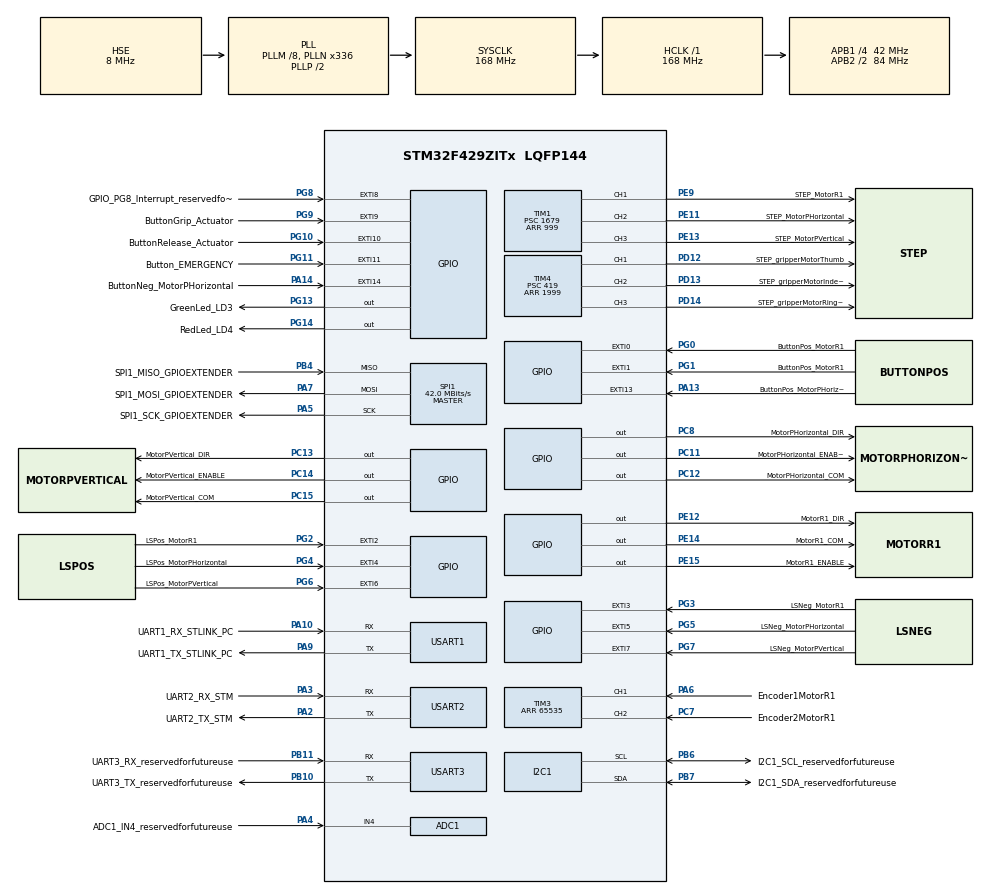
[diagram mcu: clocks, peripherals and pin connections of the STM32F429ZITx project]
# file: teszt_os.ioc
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ADC1.Channel-3\#ChannelRegularConversion=ADC_CHANNEL_4
ADC1.NbrOfConversionFlag=1
ADC1.Rank-3\#ChannelRegularConversion=1
ADC1.SamplingTime-3\#ChannelRegularConversion=ADC_SAMPLETIME_3CYCLES
ADC1.master=1
FREERTOS.BinarySemaphores01=semMotorR1,Dynamic,NULL;semMotorPHorizontal,Dynamic,NULL;semMotorPVertical,Dynamic,NULL
FREERTOS.INCLUDE_vTaskDelayUntil=1
FREERTOS.Queues01=commQueue,16,uint32_t,0,Dynamic,NULL,NULL
FREERTOS.Tasks01=defaultTask,0,256,StartDefaultTask,Default,NULL,Dynamic,NULL,NULL;controlTask,3,2048,StartRobotControlTask,Default,NULL,Dynamic,NULL,NULL;commTask,2,2048,StartCommunicationTask,Default,NULL,Dynamic,NULL,NULL
FREERTOS.configCHECK_FOR_STACK_OVERFLOW=2
FREERTOS.configTOTAL_HEAP_SIZE=32768
FREERTOS.configUSE_APPLICATION_TASK_TAG=1
FREERTOS.configUSE_COUNTING_SEMAPHORES=1
FREERTOS.configUSE_IDLE_HOOK=1
FREERTOS.configUSE_MALLOC_FAILED_HOOK=1
FREERTOS.configUSE_RECURSIVE_MUTEXES=1
FREERTOS.configUSE_TIMERS=0
Mcu.Family=STM32F4
Mcu.Name=STM32F429ZITx
Mcu.Package=LQFP144
NVIC.EXTI0_IRQn=true\:5\:0\:false\:false\:true\:true\:true\:true
NVIC.EXTI15_10_IRQn=true\:5\:0\:false\:false\:true\:true\:true\:true
NVIC.EXTI1_IRQn=true\:5\:0\:false\:false\:true\:true\:true\:true
NVIC.EXTI2_IRQn=true\:5\:0\:false\:false\:true\:true\:true\:true
NVIC.EXTI3_IRQn=true\:5\:0\:false\:false\:true\:true\:true\:true
NVIC.EXTI4_IRQn=true\:5\:0\:false\:false\:true\:true\:true\:true
NVIC.EXTI9_5_IRQn=true\:5\:0\:false\:false\:true\:true\:true\:true
NVIC.PriorityGroup=NVIC_PRIORITYGROUP_4
NVIC.TIM1_CC_IRQn=true\:5\:0\:false\:false\:true\:true\:true\:true
NVIC.TIM1_UP_TIM10_IRQn=true\:5\:0\:false\:false\:true\:true\:true\:true
NVIC.TIM6_DAC_IRQn=true\:0\:0\:false\:false\:true\:false\:false\:true
NVIC.TimeBase=TIM6_DAC_IRQn
NVIC.TimeBaseIP=TIM6
PA10.GPIO_Label=UART1_RX_STLINK_PC
PA10.Mode=Asynchronous
PA10.Signal=USART1_RX
PA13.GPIO_Label=ButtonPos_MotorPHorizontal
PA13.GPIO_ModeDefaultEXTI=GPIO_MODE_IT_RISING_FALLING
PA13.GPIO_PuPd=GPIO_PULLDOWN
PA13.Signal=GPXTI13
PA14.GPIO_Label=ButtonNeg_MotorPHorizontal
PA14.GPIO_ModeDefaultEXTI=GPIO_MODE_IT_RISING_FALLING
PA14.GPIO_PuPd=GPIO_PULLDOWN
PA14.Signal=GPXTI14
PA2.GPIO_Label=UART2_TX_STM
PA2.GPIO_Speed=GPIO_SPEED_FREQ_VERY_HIGH
PA2.Mode=Multiprocessor_communication
PA2.Signal=USART2_TX
PA3.GPIO_Label=UART2_RX_STM
PA3.Mode=Multiprocessor_communication
PA3.Signal=USART2_RX
PA4.GPIO_Label=ADC1_IN4_reservedforfutureuse
PA4.Signal=ADCx_IN4
PA5.GPIO_Label=SPI1_SCK_GPIOEXTENDER
PA5.Mode=Full_Duplex_Master
PA5.Signal=SPI1_SCK
PA6.GPIO_Label=Encoder1MotorR1
PA6.Signal=S_TIM3_CH1
PA7.GPIO_Label=SPI1_MOSI_GPIOEXTENDER
PA7.Mode=Full_Duplex_Master
PA7.Signal=SPI1_MOSI
PA9.GPIO_Label=UART1_TX_STLINK_PC
PA9.Mode=Asynchronous
PA9.Signal=USART1_TX
PB10.GPIO_Label=UART3_TX_reservedforfutureuse
PB10.Mode=Asynchronous
PB10.Signal=USART3_TX
PB11.GPIO_Label=UART3_RX_reservedforfutureuse
PB11.Mode=Asynchronous
PB11.Signal=USART3_RX
PB4.GPIO_Label=SPI1_MISO_GPIOEXTENDER
PB4.Mode=Full_Duplex_Master
PB4.Signal=SPI1_MISO
PB6.GPIO_Label=I2C1_SCL_reservedforfutureuse
PB6.Mode=I2C
PB6.Signal=I2C1_SCL
PB7.GPIO_Label=I2C1_SDA_reservedforfutureuse
PB7.Mode=I2C
PB7.Signal=I2C1_SDA
PC11.GPIO_Label=MotorPHorizontal_ENABLE
PC11.Signal=GPIO_Output
PC12.GPIO_Label=MotorPHorizontal_COM
PC12.Signal=GPIO_Output
PC13.GPIO_Label=MotorPVertical_DIR
PC13.Signal=GPIO_Output
PC14/OSC32_IN.GPIO_Label=MotorPVertical_ENABLE
PC14/OSC32_IN.Signal=GPIO_Output
PC15/OSC32_OUT.GPIO_Label=MotorPVertical_COM
PC15/OSC32_OUT.Signal=GPIO_Output
PC7.GPIO_Label=Encoder2MotorR1
PC7.Signal=S_TIM3_CH2
PC8.GPIO_Label=MotorPHorizontal_DIR
PC8.Signal=GPIO_Output
PD12.GPIO_Label=STEP_gripperMotorThumb
PD12.Signal=S_TIM4_CH1
PD13.GPIO_Label=STEP_gripperMotorIndexMiddle
PD13.Signal=S_TIM4_CH2
PD14.GPIO_Label=STEP_gripperMotorRingPinky
PD14.Signal=S_TIM4_CH3
PE11.GPIO_Label=STEP_MotorPHorizontal
PE11.GPIO_Speed=GPIO_SPEED_FREQ_HIGH
PE11.Signal=S_TIM1_CH2
PE12.GPIO_Label=MotorR1_DIR
PE12.Signal=GPIO_Output
PE13.GPIO_Label=STEP_MotorPVertical
PE13.GPIO_Speed=GPIO_SPEED_FREQ_HIGH
PE13.Signal=S_TIM1_CH3
PE14.GPIO_Label=MotorR1_COM
PE14.Signal=GPIO_Output
PE15.GPIO_Label=MotorR1_ENABLE
PE15.Signal=GPIO_Output
PE9.GPIO_Label=STEP_MotorR1
PE9.GPIO_Speed=GPIO_SPEED_FREQ_HIGH
PE9.Signal=S_TIM1_CH1
PG0.GPIO_Label=ButtonPos_MotorR1
PG0.GPIO_ModeDefaultEXTI=GPIO_MODE_IT_RISING_FALLING
PG0.GPIO_PuPd=GPIO_PULLDOWN
PG0.Signal=GPXTI0
PG1.GPIO_Label=ButtonPos_MotorR1
PG1.GPIO_ModeDefaultEXTI=GPIO_MODE_IT_RISING_FALLING
PG1.GPIO_PuPd=GPIO_PULLDOWN
PG1.Signal=GPXTI1
PG10.GPIO_Label=ButtonRelease_Actuator
PG10.GPIO_PuPd=GPIO_PULLDOWN
PG10.Signal=GPXTI10
PG11.GPIO_Label=Button_EMERGENCY
PG11.GPIO_ModeDefaultEXTI=GPIO_MODE_IT_RISING_FALLING
PG11.Signal=GPXTI11
PG13.GPIO_Label=GreenLed_LD3
PG13.GPIO_Mode=GPIO_MODE_OUTPUT_PP
PG13.GPIO_PuPd=GPIO_NOPULL
PG13.GPIO_Speed=GPIO_SPEED_FREQ_LOW
PG13.Signal=GPIO_Output
PG14.GPIO_Label=RedLed_LD4
PG14.GPIO_Mode=GPIO_MODE_OUTPUT_PP
PG14.GPIO_PuPd=GPIO_NOPULL
PG14.GPIO_Speed=GPIO_SPEED_FREQ_LOW
PG14.Signal=GPIO_Output
PG2.GPIO_Label=LSPos_MotorR1
PG2.GPIO_ModeDefaultEXTI=GPIO_MODE_IT_RISING_FALLING
PG2.Signal=GPXTI2
PG3.GPIO_Label=LSNeg_MotorR1
PG3.GPIO_ModeDefaultEXTI=GPIO_MODE_IT_RISING_FALLING
PG3.Signal=GPXTI3
PG4.GPIO_Label=LSPos_MotorPHorizontal
PG4.GPIO_ModeDefaultEXTI=GPIO_MODE_IT_RISING_FALLING
PG4.Signal=GPXTI4
PG5.GPIO_Label=LSNeg_MotorPHorizontal
PG5.GPIO_ModeDefaultEXTI=GPIO_MODE_IT_RISING_FALLING
PG5.Signal=GPXTI5
PG6.GPIO_Label=LSPos_MotorPVertical
PG6.GPIO_ModeDefaultEXTI=GPIO_MODE_IT_RISING_FALLING
PG6.Signal=GPXTI6
PG7.GPIO_Label=LSNeg_MotorPVertical
PG7.Signal=GPXTI7
PG8.GPIO_Label=GPIO_PG8_Interrupt_reservedforfutureuse
PG8.Signal=GPXTI8
PG9.GPIO_Label=ButtonGrip_Actuator
PG9.GPIO_PuPd=GPIO_PULLDOWN
PG9.Signal=GPXTI9
PH0/OSC_IN.GPIO_Label=PH0-OSC_IN
PH0/OSC_IN.Mode=HSE-External-Oscillator
PH0/OSC_IN.Signal=RCC_OSC_IN
PH1/OSC_OUT.GPIO_Label=PH1-OSC_OUT
PH1/OSC_OUT.Mode=HSE-External-Oscillator
PH1/OSC_OUT.Signal=RCC_OSC_OUT
ProjectManager.HeapSize=0x200
ProjectManager.StackSize=0x400
ProjectManager.TargetToolchain=SW4STM32
RCC.48MHZClocksFreq_Value=48000000
RCC.AHBFreq_Value=168000000
RCC.APB1CLKDivider=RCC_HCLK_DIV4
RCC.APB1Freq_Value=42000000
RCC.APB1TimFreq_Value=84000000
RCC.APB2CLKDivider=RCC_HCLK_DIV2
RCC.APB2Freq_Value=84000000
RCC.APB2TimFreq_Value=168000000
RCC.CortexFreq_Value=168000000
RCC.HCLKFreq_Value=168000000
RCC.HSE_VALUE=8000000
RCC.HSI_VALUE=16000000
RCC.LSE_VALUE=32768
RCC.PLLM=8
RCC.PLLN=336
RCC.PLLQ=7
RCC.PLLSAIN=50
RCC.PLLSourceVirtual=RCC_PLLSOURCE_HSE
RCC.SYSCLKFreq_VALUE=168000000
RCC.SYSCLKSource=RCC_SYSCLKSOURCE_PLLCLK
RCC.VCOOutputFreq_Value=336000000
SH.ADCx_IN4.0=ADC1_IN4,IN4
SH.S_TIM1_CH1.0=TIM1_CH1,PWM Generation1 CH1
SH.S_TIM1_CH2.0=TIM1_CH2,PWM Generation2 CH2
SH.S_TIM1_CH3.0=TIM1_CH3,PWM Generation3 CH3
SH.S_TIM3_CH1.0=TIM3_CH1,Encoder_Interface
SH.S_TIM3_CH2.0=TIM3_CH2,Encoder_Interface
SH.S_TIM4_CH1.0=TIM4_CH1,PWM Generation1 CH1
SH.S_TIM4_CH2.0=TIM4_CH2,PWM Generation2 CH2
SH.S_TIM4_CH3.0=TIM4_CH3,PWM Generation3 CH3
SPI1.CalculateBaudRate=42.0 MBits/s
SPI1.Direction=SPI_DIRECTION_2LINES
SPI1.Mode=SPI_MODE_MASTER
SPI1.VirtualType=VM_MASTER
TIM1.Channel-PWM\ Generation1\ CH1=TIM_CHANNEL_1
TIM1.Channel-PWM\ Generation2\ CH2=TIM_CHANNEL_2
TIM1.Channel-PWM\ Generation3\ CH3=TIM_CHANNEL_3
TIM1.OCMode_PWM-PWM\ Generation1\ CH1=TIM_OCMODE_PWM2
TIM1.OCMode_PWM-PWM\ Generation2\ CH2=TIM_OCMODE_PWM2
TIM1.OCMode_PWM-PWM\ Generation3\ CH3=TIM_OCMODE_PWM2
TIM1.Period=999
TIM1.Prescaler=1679
TIM1.Pulse-PWM\ Generation1\ CH1=499
TIM1.Pulse-PWM\ Generation2\ CH2=499
TIM1.Pulse-PWM\ Generation3\ CH3=499
TIM1.RepetitionCounter=12
TIM3.EncoderMode=TIM_ENCODERMODE_TI12
TIM3.Period=65535
TIM4.Channel-PWM\ Generation1\ CH1=TIM_CHANNEL_1
TIM4.Channel-PWM\ Generation2\ CH2=TIM_CHANNEL_2
TIM4.Channel-PWM\ Generation3\ CH3=TIM_CHANNEL_3
TIM4.ClockDivision=TIM_CLOCKDIVISION_DIV2
TIM4.OCMode_PWM-PWM\ Generation1\ CH1=TIM_OCMODE_PWM2
TIM4.OCMode_PWM-PWM\ Generation2\ CH2=TIM_OCMODE_PWM2
TIM4.OCMode_PWM-PWM\ Generation3\ CH3=TIM_OCMODE_PWM2
TIM4.Period=1999
TIM4.Prescaler=419
TIM4.Pulse-PWM\ Generation1\ CH1=15
TIM4.Pulse-PWM\ Generation2\ CH2=15
TIM4.Pulse-PWM\ Generation3\ CH3=15
USART1.VirtualMode=VM_ASYNC
USART2.VirtualMode=VM_ASYNC
USART3.VirtualMode=VM_ASYNC
VP_FREERTOS_VS_CMSIS_V1.Mode=CMSIS_V1
VP_SYS_VS_tim6.Mode=TIM6
VP_TIM1_VS_ClockSourceINT.Mode=Internal
VP_TIM1_VS_OPM.Mode=OPM_bit
VP_TIM4_VS_ClockSourceINT.Mode=Internal
board=STM32F429I-DISC1

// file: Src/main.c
/* USER CODE BEGIN Header */
/**
  ******************************************************************************
  * @file           : main.c
  * @brief          : Main program body
  ******************************************************************************
  * @attention
  *
  * <h2><center>&copy; Copyright (c) 2019 STMicroelectronics.
  * All rights reserved.</center></h2>
  *
  * This software component is licensed by ST under Ultimate Liberty license
  * SLA0044, the "License"; You may not use this file except in compliance with
  * the License. You may obtain a copy of the License at:
  *                             www.st.com/SLA0044
  *
  ******************************************************************************
  */
/* USER CODE END Header */

#include "main.h"
#include "cmsis_os.h"

/* USER CODE BEGIN Includes */
#include "mainStateMachine.h"
#include "utilityFunctions.h"
#include "motors.h"
#include "encoder.h"
#include <stdio.h>
/* USER CODE END Includes */

ADC_HandleTypeDef hadc1;

I2C_HandleTypeDef hi2c1;

SPI_HandleTypeDef hspi1;

TIM_HandleTypeDef htim1;
TIM_HandleTypeDef htim3;
TIM_HandleTypeDef htim4;

UART_HandleTypeDef huart1;
UART_HandleTypeDef huart2;
UART_HandleTypeDef huart3;

osThreadId defaultTaskHandle;
osThreadId controlTaskHandle;
osThreadId commTaskHandle;
osMessageQId commQueueHandle;
osSemaphoreId semMotorR1Handle;
osSemaphoreId semMotorPHorizontalHandle;
osSemaphoreId semMotorPVerticalHandle;
/* USER CODE BEGIN PV */
uint32_t data = 0;
/* USER CODE END PV */

void SystemClock_Config(void);
static void MX_GPIO_Init(void);
static void MX_USART1_UART_Init(void);
static void MX_TIM1_Init(void);
static void MX_TIM3_Init(void);
static void MX_TIM4_Init(void);
static void MX_USART2_UART_Init(void);
static void MX_ADC1_Init(void);
static void MX_I2C1_Init(void);
static void MX_SPI1_Init(void);
static void MX_USART3_UART_Init(void);
void StartDefaultTask(void const * argument);
void StartRobotControlTask(void const * argument);
void StartCommunicationTask(void const * argument);

int main(void)
{
  /* USER CODE BEGIN 1 */
	dtStepperMotorInit StepperMotors[3];
	StepperMotors[0] = (dtStepperMotorInit) {
			.ID = STMOTOR_R1_ID,
			.TIM_CH = TIM_CHANNEL_1,
			.TIM = &htim1,
			.enablePIN = MotorR1_ENABLE_Pin,
			.enablePORT = MotorR1_ENABLE_GPIO_Port,
			.dirPIN = MotorR1_DIR_Pin,
			.dirPORT = MotorR1_DIR_GPIO_Port
	};

	StepperMotors[1] = (dtStepperMotorInit) {
			.ID = STMOTOR_PH_ID,
			.TIM_CH = TIM_CHANNEL_2,
			.TIM = &htim1,
			.enablePIN = MotorPHorizontal_ENABLE_Pin,
			.enablePORT = MotorPHorizontal_ENABLE_GPIO_Port,
			.dirPIN = MotorPHorizontal_DIR_Pin,
			.dirPORT = MotorPHorizontal_DIR_GPIO_Port
	};

	StepperMotors[2] = (dtStepperMotorInit) {
			.ID = STMOTOR_PV_ID,
			.TIM_CH = TIM_CHANNEL_3,
			.TIM = &htim1,
			.enablePIN = MotorPVertical_ENABLE_Pin,
			.enablePORT = MotorPVertical_ENABLE_GPIO_Port,
			.dirPIN = MotorPVertical_DIR_Pin,
			.dirPORT = MotorPVertical_DIR_GPIO_Port
	};
  /* USER CODE END 1 */

  /* MCU Configuration--------------------------------------------------------*/

  /* Reset of all peripherals, Initializes the Flash interface and the Systick. */
  HAL_Init();

  /* Configure the system clock */
  SystemClock_Config();

  /* Initialize all configured peripherals */
  MX_GPIO_Init();
  MX_USART1_UART_Init();
  MX_TIM1_Init();
  MX_TIM3_Init();
  MX_TIM4_Init();
  MX_USART2_UART_Init();
  MX_ADC1_Init();
  MX_I2C1_Init();
  MX_SPI1_Init();
  MX_USART3_UART_Init();
  /* USER CODE BEGIN 2 */
  initStepperMotors(StepperMotors[0]);
  initStepperMotors(StepperMotors[1]);
  initStepperMotors(StepperMotors[2]);
  initPositions();

  initEncoder(ENCODER_NR0_ZR20, &htim3, ENCODER_NR0_MAXVALUE);

  /* USER CODE END 2 */

  /* Create the semaphores(s) */
  /* definition and creation of semMotorR1 */
  osSemaphoreDef(semMotorR1);
  semMotorR1Handle = osSemaphoreCreate(osSemaphore(semMotorR1), 1);

  /* definition and creation of semMotorPHorizontal */
  osSemaphoreDef(semMotorPHorizontal);
  semMotorPHorizontalHandle = osSemaphoreCreate(osSemaphore(semMotorPHorizontal), 1);

  /* definition and creation of semMotorPVertical */
  osSemaphoreDef(semMotorPVertical);
  semMotorPVerticalHandle = osSemaphoreCreate(osSemaphore(semMotorPVertical), 1);

  /* Create the queue(s) */
  /* definition and creation of commQueue */
  osMessageQDef(commQueue, 16, uint32_t);
  commQueueHandle = osMessageCreate(osMessageQ(commQueue), NULL);

  /* Create the thread(s) */
  /* definition and creation of defaultTask */
  osThreadDef(defaultTask, StartDefaultTask, osPriorityNormal, 0, 256);
  defaultTaskHandle = osThreadCreate(osThread(defaultTask), NULL);

  /* definition and creation of controlTask */
  osThreadDef(controlTask, StartRobotControlTask, osPriorityRealtime, 0, 2048);
  controlTaskHandle = osThreadCreate(osThread(controlTask), NULL);

  /* definition and creation of commTask */
  osThreadDef(commTask, StartCommunicationTask, osPriorityHigh, 0, 2048);
  commTaskHandle = osThreadCreate(osThread(commTask), NULL);

  /* Start scheduler */
  osKernelStart();

  /* We should never get here as control is now taken by the scheduler */

  /* Infinite loop */
  while (1)
  {

  }
}

void SystemClock_Config(void)
{
  RCC_OscInitTypeDef RCC_OscInitStruct = {0};
  RCC_ClkInitTypeDef RCC_ClkInitStruct = {0};

  /** Configure the main internal regulator output voltage
  */
  __HAL_RCC_PWR_CLK_ENABLE();
  __HAL_PWR_VOLTAGESCALING_CONFIG(PWR_REGULATOR_VOLTAGE_SCALE1);
  /** Initializes the CPU, AHB and APB busses clocks
  */
  RCC_OscInitStruct.OscillatorType = RCC_OSCILLATORTYPE_HSE;
  RCC_OscInitStruct.HSEState = RCC_HSE_ON;
  RCC_OscInitStruct.PLL.PLLState = RCC_PLL_ON;
  RCC_OscInitStruct.PLL.PLLSource = RCC_PLLSOURCE_HSE;
  RCC_OscInitStruct.PLL.PLLM = 8;
  RCC_OscInitStruct.PLL.PLLN = 336;
  RCC_OscInitStruct.PLL.PLLP = RCC_PLLP_DIV2;
  RCC_OscInitStruct.PLL.PLLQ = 7;
  if (HAL_RCC_OscConfig(&RCC_OscInitStruct) != HAL_OK)
  {
    Error_Handler();
  }
  /** Initializes the CPU, AHB and APB busses clocks
  */
  RCC_ClkInitStruct.ClockType = RCC_CLOCKTYPE_HCLK|RCC_CLOCKTYPE_SYSCLK
                              |RCC_CLOCKTYPE_PCLK1|RCC_CLOCKTYPE_PCLK2;
  RCC_ClkInitStruct.SYSCLKSource = RCC_SYSCLKSOURCE_PLLCLK;
  RCC_ClkInitStruct.AHBCLKDivider = RCC_SYSCLK_DIV1;
  RCC_ClkInitStruct.APB1CLKDivider = RCC_HCLK_DIV4;
  RCC_ClkInitStruct.APB2CLKDivider = RCC_HCLK_DIV2;

  if (HAL_RCC_ClockConfig(&RCC_ClkInitStruct, FLASH_LATENCY_5) != HAL_OK)
  {
    Error_Handler();
  }
}

static void MX_ADC1_Init(void)
{

  ADC_ChannelConfTypeDef sConfig = {0};

  /** Configure the global features of the ADC (Clock, Resolution, Data Alignment and number of conversion)
  */
  hadc1.Instance = ADC1;
  hadc1.Init.ClockPrescaler = ADC_CLOCK_SYNC_PCLK_DIV4;
  hadc1.Init.Resolution = ADC_RESOLUTION_12B;
  hadc1.Init.ScanConvMode = DISABLE;
  hadc1.Init.ContinuousConvMode = DISABLE;
  hadc1.Init.DiscontinuousConvMode = DISABLE;
  hadc1.Init.ExternalTrigConvEdge = ADC_EXTERNALTRIGCONVEDGE_NONE;
  hadc1.Init.ExternalTrigConv = ADC_SOFTWARE_START;
  hadc1.Init.DataAlign = ADC_DATAALIGN_RIGHT;
  hadc1.Init.NbrOfConversion = 1;
  hadc1.Init.DMAContinuousRequests = DISABLE;
  hadc1.Init.EOCSelection = ADC_EOC_SINGLE_CONV;
  if (HAL_ADC_Init(&hadc1) != HAL_OK)
  {
    Error_Handler();
  }
  /** Configure for the selected ADC regular channel its corresponding rank in the sequencer and its sample time.
  */
  sConfig.Channel = ADC_CHANNEL_4;
  sConfig.Rank = 1;
  sConfig.SamplingTime = ADC_SAMPLETIME_3CYCLES;
  if (HAL_ADC_ConfigChannel(&hadc1, &sConfig) != HAL_OK)
  {
    Error_Handler();
  }

}

static void MX_I2C1_Init(void)
{

  hi2c1.Instance = I2C1;
  hi2c1.Init.ClockSpeed = 100000;
  hi2c1.Init.DutyCycle = I2C_DUTYCYCLE_2;
  hi2c1.Init.OwnAddress1 = 0;
  hi2c1.Init.AddressingMode = I2C_ADDRESSINGMODE_7BIT;
  hi2c1.Init.DualAddressMode = I2C_DUALADDRESS_DISABLE;
  hi2c1.Init.OwnAddress2 = 0;
  hi2c1.Init.GeneralCallMode = I2C_GENERALCALL_DISABLE;
  hi2c1.Init.NoStretchMode = I2C_NOSTRETCH_DISABLE;
  if (HAL_I2C_Init(&hi2c1) != HAL_OK)
  {
    Error_Handler();
  }
  /** Configure Analogue filter
  */
  if (HAL_I2CEx_ConfigAnalogFilter(&hi2c1, I2C_ANALOGFILTER_ENABLE) != HAL_OK)
  {
    Error_Handler();
  }
  /** Configure Digital filter
  */
  if (HAL_I2CEx_ConfigDigitalFilter(&hi2c1, 0) != HAL_OK)
  {
    Error_Handler();
  }

}

static void MX_SPI1_Init(void)
{

  /* SPI1 parameter configuration*/
  hspi1.Instance = SPI1;
  hspi1.Init.Mode = SPI_MODE_MASTER;
  hspi1.Init.Direction = SPI_DIRECTION_2LINES;
  hspi1.Init.DataSize = SPI_DATASIZE_8BIT;
  hspi1.Init.CLKPolarity = SPI_POLARITY_LOW;
  hspi1.Init.CLKPhase = SPI_PHASE_1EDGE;
  hspi1.Init.NSS = SPI_NSS_SOFT;
  hspi1.Init.BaudRatePrescaler = SPI_BAUDRATEPRESCALER_2;
  hspi1.Init.FirstBit = SPI_FIRSTBIT_MSB;
  hspi1.Init.TIMode = SPI_TIMODE_DISABLE;
  hspi1.Init.CRCCalculation = SPI_CRCCALCULATION_DISABLE;
  hspi1.Init.CRCPolynomial = 10;
  if (HAL_SPI_Init(&hspi1) != HAL_OK)
  {
    Error_Handler();
  }

}

static void MX_TIM1_Init(void)
{

  TIM_ClockConfigTypeDef sClockSourceConfig = {0};
  TIM_MasterConfigTypeDef sMasterConfig = {0};
  TIM_OC_InitTypeDef sConfigOC = {0};
  TIM_BreakDeadTimeConfigTypeDef sBreakDeadTimeConfig = {0};

  htim1.Instance = TIM1;
  htim1.Init.Prescaler = 1679;
  htim1.Init.CounterMode = TIM_COUNTERMODE_UP;
  htim1.Init.Period = 999;
  htim1.Init.ClockDivision = TIM_CLOCKDIVISION_DIV1;
  htim1.Init.RepetitionCounter = 12;
  htim1.Init.AutoReloadPreload = TIM_AUTORELOAD_PRELOAD_DISABLE;
  if (HAL_TIM_Base_Init(&htim1) != HAL_OK)
  {
    Error_Handler();
  }
  sClockSourceConfig.ClockSource = TIM_CLOCKSOURCE_INTERNAL;
  if (HAL_TIM_ConfigClockSource(&htim1, &sClockSourceConfig) != HAL_OK)
  {
    Error_Handler();
  }
  if (HAL_TIM_PWM_Init(&htim1) != HAL_OK)
  {
    Error_Handler();
  }
  if (HAL_TIM_OnePulse_Init(&htim1, TIM_OPMODE_SINGLE) != HAL_OK)
  {
    Error_Handler();
  }
  sMasterConfig.MasterOutputTrigger = TIM_TRGO_RESET;
  sMasterConfig.MasterSlaveMode = TIM_MASTERSLAVEMODE_DISABLE;
  if (HAL_TIMEx_MasterConfigSynchronization(&htim1, &sMasterConfig) != HAL_OK)
  {
    Error_Handler();
  }
  sConfigOC.OCMode = TIM_OCMODE_PWM2;
  sConfigOC.Pulse = 499;
  sConfigOC.OCPolarity = TIM_OCPOLARITY_HIGH;
  sConfigOC.OCNPolarity = TIM_OCNPOLARITY_HIGH;
  sConfigOC.OCFastMode = TIM_OCFAST_DISABLE;
  sConfigOC.OCIdleState = TIM_OCIDLESTATE_RESET;
  sConfigOC.OCNIdleState = TIM_OCNIDLESTATE_RESET;
  if (HAL_TIM_PWM_ConfigChannel(&htim1, &sConfigOC, TIM_CHANNEL_1) != HAL_OK)
  {
    Error_Handler();
  }
  if (HAL_TIM_PWM_ConfigChannel(&htim1, &sConfigOC, TIM_CHANNEL_2) != HAL_OK)
  {
    Error_Handler();
  }
  if (HAL_TIM_PWM_ConfigChannel(&htim1, &sConfigOC, TIM_CHANNEL_3) != HAL_OK)
  {
    Error_Handler();
  }
  sBreakDeadTimeConfig.OffStateRunMode = TIM_OSSR_DISABLE;
  sBreakDeadTimeConfig.OffStateIDLEMode = TIM_OSSI_DISABLE;
  sBreakDeadTimeConfig.LockLevel = TIM_LOCKLEVEL_OFF;
  sBreakDeadTimeConfig.DeadTime = 0;
  sBreakDeadTimeConfig.BreakState = TIM_BREAK_DISABLE;
  sBreakDeadTimeConfig.BreakPolarity = TIM_BREAKPOLARITY_HIGH;
  sBreakDeadTimeConfig.AutomaticOutput = TIM_AUTOMATICOUTPUT_DISABLE;
  if (HAL_TIMEx_ConfigBreakDeadTime(&htim1, &sBreakDeadTimeConfig) != HAL_OK)
  {
    Error_Handler();
  }
  HAL_TIM_MspPostInit(&htim1);

}

static void MX_TIM3_Init(void)
{

  TIM_Encoder_InitTypeDef sConfig = {0};
  TIM_MasterConfigTypeDef sMasterConfig = {0};

  htim3.Instance = TIM3;
  htim3.Init.Prescaler = 0;
  htim3.Init.CounterMode = TIM_COUNTERMODE_UP;
  htim3.Init.Period = 65535;
  htim3.Init.ClockDivision = TIM_CLOCKDIVISION_DIV1;
  htim3.Init.AutoReloadPreload = TIM_AUTORELOAD_PRELOAD_DISABLE;
  sConfig.EncoderMode = TIM_ENCODERMODE_TI12;
  sConfig.IC1Polarity = TIM_ICPOLARITY_RISING;
  sConfig.IC1Selection = TIM_ICSELECTION_DIRECTTI;
  sConfig.IC1Prescaler = TIM_ICPSC_DIV1;
  sConfig.IC1Filter = 0;
  sConfig.IC2Polarity = TIM_ICPOLARITY_RISING;
  sConfig.IC2Selection = TIM_ICSELECTION_DIRECTTI;
  sConfig.IC2Prescaler = TIM_ICPSC_DIV1;
  sConfig.IC2Filter = 0;
  if (HAL_TIM_Encoder_Init(&htim3, &sConfig) != HAL_OK)
  {
    Error_Handler();
  }
  sMasterConfig.MasterOutputTrigger = TIM_TRGO_RESET;
  sMasterConfig.MasterSlaveMode = TIM_MASTERSLAVEMODE_DISABLE;
  if (HAL_TIMEx_MasterConfigSynchronization(&htim3, &sMasterConfig) != HAL_OK)
  {
    Error_Handler();
  }

}

static void MX_TIM4_Init(void)
{

  TIM_ClockConfigTypeDef sClockSourceConfig = {0};
  TIM_MasterConfigTypeDef sMasterConfig = {0};
  TIM_OC_InitTypeDef sConfigOC = {0};

  htim4.Instance = TIM4;
  htim4.Init.Prescaler = 419;
  htim4.Init.CounterMode = TIM_COUNTERMODE_UP;
  htim4.Init.Period = 1999;
  htim4.Init.ClockDivision = TIM_CLOCKDIVISION_DIV2;
  htim4.Init.AutoReloadPreload = TIM_AUTORELOAD_PRELOAD_DISABLE;
  if (HAL_TIM_Base_Init(&htim4) != HAL_OK)
  {
    Error_Handler();
  }
  sClockSourceConfig.ClockSource = TIM_CLOCKSOURCE_INTERNAL;
  if (HAL_TIM_ConfigClockSource(&htim4, &sClockSourceConfig) != HAL_OK)
  {
    Error_Handler();
  }
  if (HAL_TIM_PWM_Init(&htim4) != HAL_OK)
  {
    Error_Handler();
  }
  sMasterConfig.MasterOutputTrigger = TIM_TRGO_RESET;
  sMasterConfig.MasterSlaveMode = TIM_MASTERSLAVEMODE_DISABLE;
  if (HAL_TIMEx_MasterConfigSynchronization(&htim4, &sMasterConfig) != HAL_OK)
  {
    Error_Handler();
  }
  sConfigOC.OCMode = TIM_OCMODE_PWM2;
  sConfigOC.Pulse = 15;
  sConfigOC.OCPolarity = TIM_OCPOLARITY_HIGH;
  sConfigOC.OCFastMode = TIM_OCFAST_DISABLE;
  if (HAL_TIM_PWM_ConfigChannel(&htim4, &sConfigOC, TIM_CHANNEL_1) != HAL_OK)
  {
    Error_Handler();
  }
  if (HAL_TIM_PWM_ConfigChannel(&htim4, &sConfigOC, TIM_CHANNEL_2) != HAL_OK)
  {
    Error_Handler();
  }
  if (HAL_TIM_PWM_ConfigChannel(&htim4, &sConfigOC, TIM_CHANNEL_3) != HAL_OK)
  {
    Error_Handler();
  }
  HAL_TIM_MspPostInit(&htim4);

}

static void MX_USART1_UART_Init(void)
{

  huart1.Instance = USART1;
  huart1.Init.BaudRate = 115200;
  huart1.Init.WordLength = UART_WORDLENGTH_8B;
  huart1.Init.StopBits = UART_STOPBITS_1;
  huart1.Init.Parity = UART_PARITY_NONE;
  huart1.Init.Mode = UART_MODE_TX_RX;
  huart1.Init.HwFlowCtl = UART_HWCONTROL_NONE;
  huart1.Init.OverSampling = UART_OVERSAMPLING_16;
  if (HAL_UART_Init(&huart1) != HAL_OK)
  {
    Error_Handler();
  }

}

static void MX_USART2_UART_Init(void)
{

  huart2.Instance = USART2;
  huart2.Init.BaudRate = 115200;
  huart2.Init.WordLength = UART_WORDLENGTH_8B;
  huart2.Init.StopBits = UART_STOPBITS_1;
  huart2.Init.Parity = UART_PARITY_NONE;
  huart2.Init.Mode = UART_MODE_TX_RX;
  huart2.Init.HwFlowCtl = UART_HWCONTROL_NONE;
  huart2.Init.OverSampling = UART_OVERSAMPLING_16;
  if (HAL_MultiProcessor_Init(&huart2, 0, UART_WAKEUPMETHOD_IDLELINE) != HAL_OK)
  {
    Error_Handler();
  }

}

static void MX_USART3_UART_Init(void)
{

  huart3.Instance = USART3;
  huart3.Init.BaudRate = 115200;
  huart3.Init.WordLength = UART_WORDLENGTH_8B;
  huart3.Init.StopBits = UART_STOPBITS_1;
  huart3.Init.Parity = UART_PARITY_NONE;
  huart3.Init.Mode = UART_MODE_TX_RX;
  huart3.Init.HwFlowCtl = UART_HWCONTROL_NONE;
  huart3.Init.OverSampling = UART_OVERSAMPLING_16;
  if (HAL_UART_Init(&huart3) != HAL_OK)
  {
    Error_Handler();
  }

}

static void MX_GPIO_Init(void)
{
  GPIO_InitTypeDef GPIO_InitStruct = {0};

  /* GPIO Ports Clock Enable */
  __HAL_RCC_GPIOC_CLK_ENABLE();
  __HAL_RCC_GPIOH_CLK_ENABLE();
  __HAL_RCC_GPIOA_CLK_ENABLE();
  __HAL_RCC_GPIOG_CLK_ENABLE();
  __HAL_RCC_GPIOE_CLK_ENABLE();
  __HAL_RCC_GPIOB_CLK_ENABLE();
  __HAL_RCC_GPIOD_CLK_ENABLE();

  /*Configure GPIO pin Output Level */
  HAL_GPIO_WritePin(GPIOC, MotorPVertical_DIR_Pin|MotorPVertical_ENABLE_Pin|MotorPVertical_COM_Pin|MotorPHorizontal_DIR_Pin
                          |MotorPHorizontal_ENABLE_Pin|MotorPHorizontal_COM_Pin, GPIO_PIN_RESET);

  /*Configure GPIO pin Output Level */
  HAL_GPIO_WritePin(GPIOE, MotorR1_DIR_Pin|MotorR1_COM_Pin|MotorR1_ENABLE_Pin, GPIO_PIN_RESET);

  /*Configure GPIO pin Output Level */
  HAL_GPIO_WritePin(GPIOG, GreenLed_LD3_Pin|RedLed_LD4_Pin, GPIO_PIN_RESET);

  /*Configure GPIO pin : PA0 */
  GPIO_InitStruct.Pin = GPIO_PIN_0;
  GPIO_InitStruct.Mode = GPIO_MODE_INPUT;
  GPIO_InitStruct.Pull = GPIO_NOPULL;
  HAL_GPIO_Init(GPIOA, &GPIO_InitStruct);

  /*Configure GPIO pins : MotorPVertical_DIR_Pin MotorPVertical_ENABLE_Pin MotorPVertical_COM_Pin MotorPHorizontal_DIR_Pin
                           MotorPHorizontal_ENABLE_Pin MotorPHorizontal_COM_Pin */
  GPIO_InitStruct.Pin = MotorPVertical_DIR_Pin|MotorPVertical_ENABLE_Pin|MotorPVertical_COM_Pin|MotorPHorizontal_DIR_Pin
                          |MotorPHorizontal_ENABLE_Pin|MotorPHorizontal_COM_Pin;
  GPIO_InitStruct.Mode = GPIO_MODE_OUTPUT_PP;
  GPIO_InitStruct.Pull = GPIO_NOPULL;
  GPIO_InitStruct.Speed = GPIO_SPEED_FREQ_LOW;
  HAL_GPIO_Init(GPIOC, &GPIO_InitStruct);

  /*Configure GPIO pins : ButtonPos_MotorR1_Pin ButtonPos_MotorR1G1_Pin */
  GPIO_InitStruct.Pin = ButtonPos_MotorR1_Pin|ButtonPos_MotorR1G1_Pin;
  GPIO_InitStruct.Mode = GPIO_MODE_IT_RISING_FALLING;
  GPIO_InitStruct.Pull = GPIO_PULLDOWN;
  HAL_GPIO_Init(GPIOG, &GPIO_InitStruct);

  /*Configure GPIO pins : MotorR1_DIR_Pin MotorR1_COM_Pin MotorR1_ENABLE_Pin */
  GPIO_InitStruct.Pin = MotorR1_DIR_Pin|MotorR1_COM_Pin|MotorR1_ENABLE_Pin;
  GPIO_InitStruct.Mode = GPIO_MODE_OUTPUT_PP;
  GPIO_InitStruct.Pull = GPIO_NOPULL;
  GPIO_InitStruct.Speed = GPIO_SPEED_FREQ_LOW;
  HAL_GPIO_Init(GPIOE, &GPIO_InitStruct);

  /*Configure GPIO pins : LSPos_MotorR1_Pin LSNeg_MotorR1_Pin LSPos_MotorPHorizontal_Pin LSNeg_MotorPHorizontal_Pin
                           LSPos_MotorPVertical_Pin Button_EMERGENCY_Pin */
  GPIO_InitStruct.Pin = LSPos_MotorR1_Pin|LSNeg_MotorR1_Pin|LSPos_MotorPHorizontal_Pin|LSNeg_MotorPHorizontal_Pin
                          |LSPos_MotorPVertical_Pin|Button_EMERGENCY_Pin;
  GPIO_InitStruct.Mode = GPIO_MODE_IT_RISING_FALLING;
  GPIO_InitStruct.Pull = GPIO_NOPULL;
  HAL_GPIO_Init(GPIOG, &GPIO_InitStruct);

  /*Configure GPIO pins : LSNeg_MotorPVertical_Pin GPIO_PG8_Interrupt_reservedforfutureuse_Pin */
  GPIO_InitStruct.Pin = LSNeg_MotorPVertical_Pin|GPIO_PG8_Interrupt_reservedforfutureuse_Pin;
  GPIO_InitStruct.Mode = GPIO_MODE_IT_RISING;
  GPIO_InitStruct.Pull = GPIO_NOPULL;
  HAL_GPIO_Init(GPIOG, &GPIO_InitStruct);

  /*Configure GPIO pins : ButtonPos_MotorPHorizontal_Pin ButtonNeg_MotorPHorizontal_Pin */
  GPIO_InitStruct.Pin = ButtonPos_MotorPHorizontal_Pin|ButtonNeg_MotorPHorizontal_Pin;
  GPIO_InitStruct.Mode = GPIO_MODE_IT_RISING_FALLING;
  GPIO_InitStruct.Pull = GPIO_PULLDOWN;
  HAL_GPIO_Init(GPIOA, &GPIO_InitStruct);

  /*Configure GPIO pins : ButtonGrip_Actuator_Pin ButtonRelease_Actuator_Pin */
  GPIO_InitStruct.Pin = ButtonGrip_Actuator_Pin|ButtonRelease_Actuator_Pin;
  GPIO_InitStruct.Mode = GPIO_MODE_IT_RISING;
  GPIO_InitStruct.Pull = GPIO_PULLDOWN;
  HAL_GPIO_Init(GPIOG, &GPIO_InitStruct);

  /*Configure GPIO pins : GreenLed_LD3_Pin RedLed_LD4_Pin */
  GPIO_InitStruct.Pin = GreenLed_LD3_Pin|RedLed_LD4_Pin;
  GPIO_InitStruct.Mode = GPIO_MODE_OUTPUT_PP;
  GPIO_InitStruct.Pull = GPIO_NOPULL;
  GPIO_InitStruct.Speed = GPIO_SPEED_FREQ_LOW;
  HAL_GPIO_Init(GPIOG, &GPIO_InitStruct);

  /* EXTI interrupt init*/
  HAL_NVIC_SetPriority(EXTI0_IRQn, 5, 0);
  HAL_NVIC_EnableIRQ(EXTI0_IRQn);

  HAL_NVIC_SetPriority(EXTI1_IRQn, 5, 0);
  HAL_NVIC_EnableIRQ(EXTI1_IRQn);

  HAL_NVIC_SetPriority(EXTI2_IRQn, 5, 0);
  HAL_NVIC_EnableIRQ(EXTI2_IRQn);

  HAL_NVIC_SetPriority(EXTI3_IRQn, 5, 0);
  HAL_NVIC_EnableIRQ(EXTI3_IRQn);

  HAL_NVIC_SetPriority(EXTI4_IRQn, 5, 0);
  HAL_NVIC_EnableIRQ(EXTI4_IRQn);

  HAL_NVIC_SetPriority(EXTI9_5_IRQn, 5, 0);
  HAL_NVIC_EnableIRQ(EXTI9_5_IRQn);

  HAL_NVIC_SetPriority(EXTI15_10_IRQn, 5, 0);
  HAL_NVIC_EnableIRQ(EXTI15_10_IRQn);

}

void StartDefaultTask(void const * argument)
{

  for(;;)
  {
  }
}

void StartRobotControlTask(void const * argument)
{
  /* USER CODE BEGIN StartRobotControlTask */
  uint8_t temp_08 = 0;

  TickType_t xLastWakeTime;
  const TickType_t xDelay10ms = pdMS_TO_TICKS(10);

  /* The xLastWakeTime variable needs to be initialized with the current tick
   * count. Note that this is the only time the variable is written to explicitly.
   * After this xLastWakeTime is automatically updated within vTaskDelayUntil(). */
  xLastWakeTime = xTaskGetTickCount();

  /* create the function pointer and set to reset state*/
  struct MSM_state msmState_ptr = {
		  .next = msmStateReset,
		  .stateName = MSM_STATE_RESET
  };

  /* Infinite loop */
  for(;;)
  {

	/* running the next state */
	temp_08 = msmState_ptr.next(&msmState_ptr);

	/* this makes the task to run at the prescribed fixed frequency */
	osDelayUntil(&xLastWakeTime, xDelay10ms);
	//osDelay(1);
  }
  /* USER CODE END StartRobotControlTask */
}

void StartCommunicationTask(void const * argument)
{
  /* USER CODE BEGIN StartCommunicationTask */
  uint8_t temp_08 = 3;
  uint8_t temp_b = 0;
  uint32_t temp_32 = 0;
  char DEBUGMSG_10[48] = {""};
  char DEBUGMSG_CNT[12] = {""};
  TickType_t xLastWakeTime;
  const TickType_t xDelay250ms = pdMS_TO_TICKS(25);

  /* The xLastWakeTime variable needs to be initialized with the current tick
   * count. Note that this is the only time the variable is written to explicitly.
   * After this xLastWakeTime is automatically updated within vTaskDelayUntil(). */
  xLastWakeTime = xTaskGetTickCount();

  /* Infinite loop */
  for(;;)
  {

	/* prints the current and desired positions to serial - recommendation: use XTCO program as serial console*/
	sprintf(DEBUGMSG_10, "{R1,PH,PV}:{%4lu(%4lu), %4lu(%4lu), %4lu(%4lu)}", getSTMotorCurrPos(STMOTOR_R1_ID), getSTMotorDesiredPos(STMOTOR_R1_ID), getSTMotorCurrPos(STMOTOR_PH_ID), getSTMotorDesiredPos(STMOTOR_PH_ID), getSTMotorCurrPos(STMOTOR_PV_ID), getSTMotorDesiredPos(STMOTOR_PV_ID));
	//HAL_UART_Transmit(&huart1, (uint8_t*)(&DEBUGMSG_10), sizeof(DEBUGMSG_10)/sizeof(DEBUGMSG_10[0]), 1000);
	temp_32 = getEncoderValue();
	sprintf(DEBUGMSG_CNT, "cnt:%lu\n", temp_32);
	HAL_UART_Transmit(&huart1, (uint8_t*)(&DEBUGMSG_CNT), sizeof(DEBUGMSG_CNT)/sizeof(DEBUGMSG_CNT[0]), 1000);

	/* this makes the task to run at the prescribed fixed frequency */
	osDelayUntil(&xLastWakeTime, xDelay250ms);
	//osDelay(1);
  }
  /* USER CODE END StartCommunicationTask */
}

void HAL_TIM_PeriodElapsedCallback(TIM_HandleTypeDef *htim)
{
  if (htim->Instance == TIM6) {
    HAL_IncTick();
  }
}

void Error_Handler(void)
{
}

/************************ (C) COPYRIGHT STMicroelectronics *****END OF FILE****/
